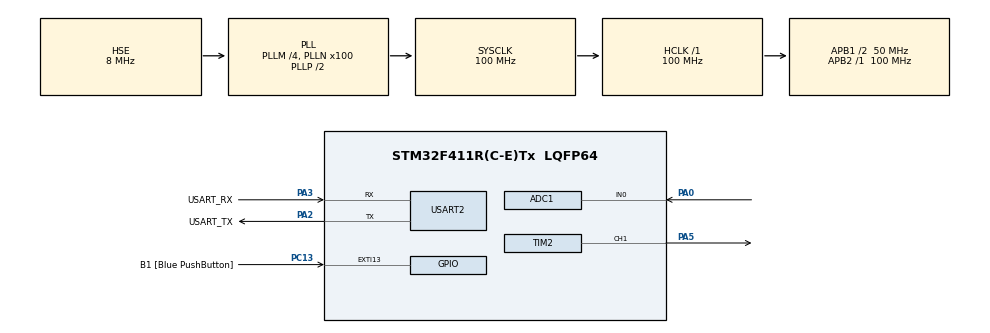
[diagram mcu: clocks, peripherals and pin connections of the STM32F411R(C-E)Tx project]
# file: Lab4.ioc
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ADC1.Channel-0\#ChannelRegularConversion=ADC_CHANNEL_0
ADC1.NbrOfConversionFlag=1
ADC1.Rank-0\#ChannelRegularConversion=1
ADC1.SamplingTime-0\#ChannelRegularConversion=ADC_SAMPLETIME_3CYCLES
ADC1.master=1
Mcu.Family=STM32F4
Mcu.Name=STM32F411R(C-E)Tx
Mcu.Package=LQFP64
NVIC.PriorityGroup=NVIC_PRIORITYGROUP_0
PA0-WKUP.Signal=ADCx_IN0
PA13.GPIO_Label=TMS
PA13.Mode=Serial_Wire
PA13.Signal=SYS_JTMS-SWDIO
PA14.GPIO_Label=TCK
PA14.Mode=Serial_Wire
PA14.Signal=SYS_JTCK-SWCLK
PA2.GPIO_Label=USART_TX
PA2.Mode=Asynchronous
PA2.Signal=USART2_TX
PA3.GPIO_Label=USART_RX
PA3.Mode=Asynchronous
PA3.Signal=USART2_RX
PA5.Signal=S_TIM2_CH1_ETR
PB3.GPIO_Label=SWO
PB3.Signal=SYS_JTDO-SWO
PC13-ANTI_TAMP.GPIO_Label=B1 [Blue PushButton]
PC13-ANTI_TAMP.GPIO_ModeDefaultEXTI=GPIO_MODE_IT_FALLING
PC13-ANTI_TAMP.Signal=GPXTI13
PC14-OSC32_IN.Mode=LSE-External-Oscillator
PC14-OSC32_IN.Signal=RCC_OSC32_IN
PC15-OSC32_OUT.Mode=LSE-External-Oscillator
PC15-OSC32_OUT.Signal=RCC_OSC32_OUT
PH0\ -\ OSC_IN.Mode=HSE-External-Clock-Source
PH0\ -\ OSC_IN.Signal=RCC_OSC_IN
PH1\ -\ OSC_OUT.Mode=HSE-External-Clock-Source
PH1\ -\ OSC_OUT.Signal=RCC_OSC_OUT
ProjectManager.HeapSize=0x200
ProjectManager.StackSize=0x400
ProjectManager.TargetToolchain=STM32CubeIDE
RCC.48MHZClocksFreq_Value=50000000
RCC.AHBFreq_Value=100000000
RCC.APB1CLKDivider=RCC_HCLK_DIV2
RCC.APB1Freq_Value=50000000
RCC.APB1TimFreq_Value=100000000
RCC.APB2Freq_Value=100000000
RCC.APB2TimFreq_Value=100000000
RCC.CortexFreq_Value=100000000
RCC.FLatency-AdvancedSettings=FLASH_LATENCY_3
RCC.HCLKFreq_Value=100000000
RCC.HSE_VALUE=8000000
RCC.HSI_VALUE=16000000
RCC.PLLM=4
RCC.PLLN=100
RCC.PLLSourceVirtual=RCC_PLLSOURCE_HSE
RCC.SYSCLKFreq_VALUE=100000000
RCC.SYSCLKSource=RCC_SYSCLKSOURCE_PLLCLK
RCC.VCOOutputFreq_Value=200000000
SH.ADCx_IN0.0=ADC1_IN0,IN0
SH.S_TIM2_CH1_ETR.0=TIM2_CH1,PWM Generation1 CH1
TIM2.AutoReloadPreload=TIM_AUTORELOAD_PRELOAD_ENABLE
TIM2.Channel-PWM\ Generation1\ CH1=TIM_CHANNEL_1
TIM2.Period=100
TIM2.Prescaler=100
USART2.VirtualMode=VM_ASYNC
VP_TIM2_VS_ClockSourceINT.Mode=Internal
board=NUCLEO-F411RE

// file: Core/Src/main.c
/* USER CODE BEGIN Header */
/**
  ******************************************************************************
  * @file           : main.c
  * @brief          : Main program body
  ******************************************************************************
  * @attention
  *
  * Copyright (c) 2023 STMicroelectronics.
  * All rights reserved.
  *
  * This software is licensed under terms that can be found in the LICENSE file
  * in the root directory of this software component.
  * If no LICENSE file comes with this software, it is provided AS-IS.
  *
  ******************************************************************************
  */
/* USER CODE END Header */
#include "main.h"

ADC_HandleTypeDef hadc1;

TIM_HandleTypeDef htim2;

UART_HandleTypeDef huart2;

void SystemClock_Config(void);
static void MX_GPIO_Init(void);
static void MX_USART2_UART_Init(void);
static void MX_TIM2_Init(void);
static void MX_ADC1_Init(void);

int main(void)
{

  /* MCU Configuration--------------------------------------------------------*/

  /* Reset of all peripherals, Initializes the Flash interface and the Systick. */
  HAL_Init();

  /* Configure the system clock */
  SystemClock_Config();

  /* Initialize all configured peripherals */
  MX_GPIO_Init();
  MX_USART2_UART_Init();
  MX_TIM2_Init();
  MX_ADC1_Init();
  /* USER CODE BEGIN 2 */
  // Lab 4.1 and 4.3: Preprocess
   HAL_TIM_PWM_Start(&htim2, TIM_CHANNEL_1);
  /* USER CODE END 2 */

  /* Infinite loop */
  /* USER CODE BEGIN WHILE */
  int state=1;
  while (1)
  {
//	Lab 4.1: DIM a red LED (LD5) by increasing the duty cycle from 0% duty cycle by 1% every 0.01 second. When the PWM reaches the 100% duty cycle, decrease the duty cycle by 1% every 0.01 second to 0% duty cycle. Repeat the following step forever. (use 100 microseconds period for PWM)
	 int currentPulse = TIM2->CCR1;
	 if(state == 1 && currentPulse == 100)
	 	state = -1;
	 else if(state == -1 && currentPulse == 0)
	 	state = 1;
	 TIM2->CCR1+=state;
	 HAL_Delay(10);

//	Lab 4.2: Lab 4.2: Connect LDR to STM32F4Discovery Board and create a new STM32 Project on System Workbench IDE to read the value from LDR and display to serial terminal via UART
//	Lab 4.3: control a red LED (LD5) brightness with PWM from the value of LDR with this equation
//	 int currentPulse = TIM2->CCR1;
//	 HAL_ADC_Start(&hadc1);
//	 int adcValue;
//	 int mx = 4095,mn = 2300;
//	 uint8_t buffer[4];
//	 if(HAL_ADC_PollForConversion(&hadc1, 100) == HAL_OK){
//	 	adcValue = HAL_ADC_GetValue(&hadc1);
//	 	int C = mx - adcValue;
//		int P = mx - mn;
//		TIM2->CCR1 = (int )((1-((double )C/P)) * 100);
//
//		HAL_UART_Transmit(&huart2, itoa(adcValue, buffer, 10), 4, 100);
////		HAL_UART_Transmit(&huart2, itoa((int )((1-((double )C/P)) * 100), buffer, 10), 4, 100);
//		HAL_UART_Transmit(&huart2, "\n\r", 2, 100);
//	 }
    /* USER CODE END WHILE */

  }
}

void SystemClock_Config(void)
{
  RCC_OscInitTypeDef RCC_OscInitStruct = {0};
  RCC_ClkInitTypeDef RCC_ClkInitStruct = {0};

  /** Configure the main internal regulator output voltage
  */
  __HAL_RCC_PWR_CLK_ENABLE();
  __HAL_PWR_VOLTAGESCALING_CONFIG(PWR_REGULATOR_VOLTAGE_SCALE1);

  /** Initializes the RCC Oscillators according to the specified parameters
  * in the RCC_OscInitTypeDef structure.
  */
  RCC_OscInitStruct.OscillatorType = RCC_OSCILLATORTYPE_HSE;
  RCC_OscInitStruct.HSEState = RCC_HSE_BYPASS;
  RCC_OscInitStruct.PLL.PLLState = RCC_PLL_ON;
  RCC_OscInitStruct.PLL.PLLSource = RCC_PLLSOURCE_HSE;
  RCC_OscInitStruct.PLL.PLLM = 4;
  RCC_OscInitStruct.PLL.PLLN = 100;
  RCC_OscInitStruct.PLL.PLLP = RCC_PLLP_DIV2;
  RCC_OscInitStruct.PLL.PLLQ = 4;
  if (HAL_RCC_OscConfig(&RCC_OscInitStruct) != HAL_OK)
  {
    Error_Handler();
  }

  /** Initializes the CPU, AHB and APB buses clocks
  */
  RCC_ClkInitStruct.ClockType = RCC_CLOCKTYPE_HCLK|RCC_CLOCKTYPE_SYSCLK
                              |RCC_CLOCKTYPE_PCLK1|RCC_CLOCKTYPE_PCLK2;
  RCC_ClkInitStruct.SYSCLKSource = RCC_SYSCLKSOURCE_PLLCLK;
  RCC_ClkInitStruct.AHBCLKDivider = RCC_SYSCLK_DIV1;
  RCC_ClkInitStruct.APB1CLKDivider = RCC_HCLK_DIV2;
  RCC_ClkInitStruct.APB2CLKDivider = RCC_HCLK_DIV1;

  if (HAL_RCC_ClockConfig(&RCC_ClkInitStruct, FLASH_LATENCY_3) != HAL_OK)
  {
    Error_Handler();
  }
}

static void MX_ADC1_Init(void)
{

  ADC_ChannelConfTypeDef sConfig = {0};

  /** Configure the global features of the ADC (Clock, Resolution, Data Alignment and number of conversion)
  */
  hadc1.Instance = ADC1;
  hadc1.Init.ClockPrescaler = ADC_CLOCK_SYNC_PCLK_DIV4;
  hadc1.Init.Resolution = ADC_RESOLUTION_12B;
  hadc1.Init.ScanConvMode = DISABLE;
  hadc1.Init.ContinuousConvMode = DISABLE;
  hadc1.Init.DiscontinuousConvMode = DISABLE;
  hadc1.Init.ExternalTrigConvEdge = ADC_EXTERNALTRIGCONVEDGE_NONE;
  hadc1.Init.ExternalTrigConv = ADC_SOFTWARE_START;
  hadc1.Init.DataAlign = ADC_DATAALIGN_RIGHT;
  hadc1.Init.NbrOfConversion = 1;
  hadc1.Init.DMAContinuousRequests = DISABLE;
  hadc1.Init.EOCSelection = ADC_EOC_SINGLE_CONV;
  if (HAL_ADC_Init(&hadc1) != HAL_OK)
  {
    Error_Handler();
  }

  /** Configure for the selected ADC regular channel its corresponding rank in the sequencer and its sample time.
  */
  sConfig.Channel = ADC_CHANNEL_0;
  sConfig.Rank = 1;
  sConfig.SamplingTime = ADC_SAMPLETIME_3CYCLES;
  if (HAL_ADC_ConfigChannel(&hadc1, &sConfig) != HAL_OK)
  {
    Error_Handler();
  }

}

static void MX_TIM2_Init(void)
{

  TIM_ClockConfigTypeDef sClockSourceConfig = {0};
  TIM_MasterConfigTypeDef sMasterConfig = {0};
  TIM_OC_InitTypeDef sConfigOC = {0};

  htim2.Instance = TIM2;
  htim2.Init.Prescaler = 100;
  htim2.Init.CounterMode = TIM_COUNTERMODE_UP;
  htim2.Init.Period = 100;
  htim2.Init.ClockDivision = TIM_CLOCKDIVISION_DIV1;
  htim2.Init.AutoReloadPreload = TIM_AUTORELOAD_PRELOAD_ENABLE;
  if (HAL_TIM_Base_Init(&htim2) != HAL_OK)
  {
    Error_Handler();
  }
  sClockSourceConfig.ClockSource = TIM_CLOCKSOURCE_INTERNAL;
  if (HAL_TIM_ConfigClockSource(&htim2, &sClockSourceConfig) != HAL_OK)
  {
    Error_Handler();
  }
  if (HAL_TIM_PWM_Init(&htim2) != HAL_OK)
  {
    Error_Handler();
  }
  sMasterConfig.MasterOutputTrigger = TIM_TRGO_RESET;
  sMasterConfig.MasterSlaveMode = TIM_MASTERSLAVEMODE_DISABLE;
  if (HAL_TIMEx_MasterConfigSynchronization(&htim2, &sMasterConfig) != HAL_OK)
  {
    Error_Handler();
  }
  sConfigOC.OCMode = TIM_OCMODE_PWM1;
  sConfigOC.Pulse = 0;
  sConfigOC.OCPolarity = TIM_OCPOLARITY_HIGH;
  sConfigOC.OCFastMode = TIM_OCFAST_DISABLE;
  if (HAL_TIM_PWM_ConfigChannel(&htim2, &sConfigOC, TIM_CHANNEL_1) != HAL_OK)
  {
    Error_Handler();
  }
  HAL_TIM_MspPostInit(&htim2);

}

static void MX_USART2_UART_Init(void)
{

  huart2.Instance = USART2;
  huart2.Init.BaudRate = 115200;
  huart2.Init.WordLength = UART_WORDLENGTH_8B;
  huart2.Init.StopBits = UART_STOPBITS_1;
  huart2.Init.Parity = UART_PARITY_NONE;
  huart2.Init.Mode = UART_MODE_TX_RX;
  huart2.Init.HwFlowCtl = UART_HWCONTROL_NONE;
  huart2.Init.OverSampling = UART_OVERSAMPLING_16;
  if (HAL_UART_Init(&huart2) != HAL_OK)
  {
    Error_Handler();
  }

}

static void MX_GPIO_Init(void)
{
  GPIO_InitTypeDef GPIO_InitStruct = {0};

  /* GPIO Ports Clock Enable */
  __HAL_RCC_GPIOC_CLK_ENABLE();
  __HAL_RCC_GPIOH_CLK_ENABLE();
  __HAL_RCC_GPIOA_CLK_ENABLE();
  __HAL_RCC_GPIOB_CLK_ENABLE();

  /*Configure GPIO pin : B1_Pin */
  GPIO_InitStruct.Pin = B1_Pin;
  GPIO_InitStruct.Mode = GPIO_MODE_IT_FALLING;
  GPIO_InitStruct.Pull = GPIO_NOPULL;
  HAL_GPIO_Init(B1_GPIO_Port, &GPIO_InitStruct);

}

void Error_Handler(void)
{
  __disable_irq();
  while (1)
  {
  }
}
